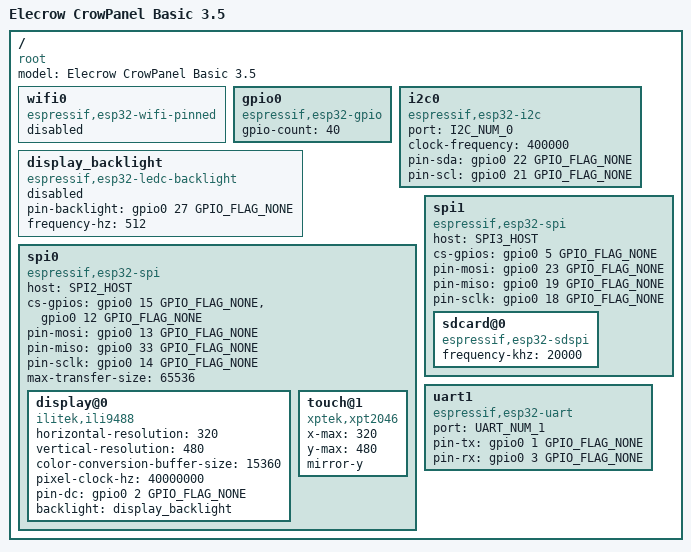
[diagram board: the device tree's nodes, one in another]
/dts-v1/;

#include <tactility/bindings/root.h>
#include <tactility/bindings/esp32_wifi_pinned.h>
#include <tactility/bindings/esp32_gpio.h>
#include <tactility/bindings/esp32_i2c.h>
#include <tactility/bindings/esp32_spi.h>
#include <tactility/bindings/esp32_uart.h>
#include <tactility/bindings/esp32_sdspi.h>
#include <tactility/bindings/esp32_ledc_backlight.h>
#include <bindings/ili9488.h>
#include <bindings/xpt2046.h>

/ {
	compatible = "root";
	model = "Elecrow CrowPanel Basic 3.5";

	wifi0 {
		compatible = "espressif,esp32-wifi-pinned";
		status = "disabled";
	};

	gpio0 {
		compatible = "espressif,esp32-gpio";
		gpio-count = <40>;
	};

	i2c0 {
		compatible = "espressif,esp32-i2c";
		port = <I2C_NUM_0>;
		clock-frequency = <400000>;
		pin-sda = <&gpio0 22 GPIO_FLAG_NONE>;
		pin-scl = <&gpio0 21 GPIO_FLAG_NONE>;
	};

	display_backlight {
		compatible = "espressif,esp32-ledc-backlight";
		// Off by default so display power-on won't show the screen from before the last power loss.
		// The display backlight is turned on during the boot process.
		status = "disabled";
		pin-backlight = <&gpio0 27 GPIO_FLAG_NONE>;
		frequency-hz = <512>;
	};

	spi0 {
		compatible = "espressif,esp32-spi";
		host = <SPI2_HOST>;
		cs-gpios = <&gpio0 15 GPIO_FLAG_NONE>, // Display
		            <&gpio0 12 GPIO_FLAG_NONE>; // Touch
		pin-mosi = <&gpio0 13 GPIO_FLAG_NONE>;
		pin-miso = <&gpio0 33 GPIO_FLAG_NONE>;
		pin-sclk = <&gpio0 14 GPIO_FLAG_NONE>;
		max-transfer-size = <65536>;

		display@0 {
			compatible = "ilitek,ili9488";
			horizontal-resolution = <320>;
			vertical-resolution = <480>;
			color-conversion-buffer-size = <15360>;
			pixel-clock-hz = <40000000>;
			pin-dc = <&gpio0 2 GPIO_FLAG_NONE>;
			backlight = <&display_backlight>;
		};

		touch@1 {
			compatible = "xptek,xpt2046";
			x-max = <320>;
			y-max = <480>;
			mirror-y;
		};
	};

	spi1 {
		compatible = "espressif,esp32-spi";
		host = <SPI3_HOST>;
		cs-gpios = <&gpio0 5 GPIO_FLAG_NONE>;
		pin-mosi = <&gpio0 23 GPIO_FLAG_NONE>;
		pin-miso = <&gpio0 19 GPIO_FLAG_NONE>;
		pin-sclk = <&gpio0 18 GPIO_FLAG_NONE>;
	
		sdcard@0 {
			compatible = "espressif,esp32-sdspi";
			frequency-khz = <20000>;
		};
	};

	uart1 {
		compatible = "espressif,esp32-uart";
		port = <UART_NUM_1>;
		pin-tx = <&gpio0 1 GPIO_FLAG_NONE>;
		pin-rx = <&gpio0 3 GPIO_FLAG_NONE>;
	};
};
